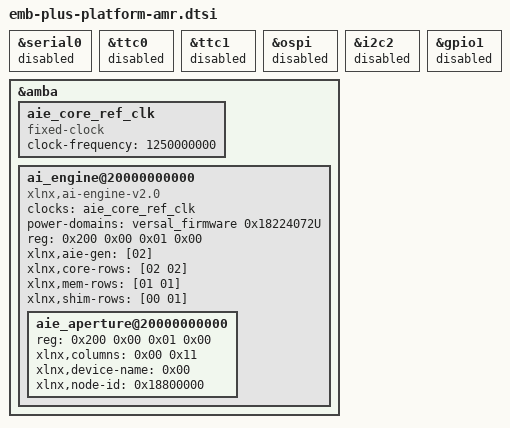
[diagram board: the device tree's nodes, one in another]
/*
 * SPDX-License-Identifier: GPL-2.0-only
 *
 * dtsi for Embedded Plus platform
 *
 * Copyright (C) 2024, Advanced Micro Devices, Inc.  All rights reserved.
 *
 */

&serial0 {
        status = "disabled";
};

&ttc0 {
        status = "disabled";
};
&ttc1 {
        status = "disabled";
};

&ospi {
        status = "disabled";
};

&i2c2 {
        status = "disabled";
};

&gpio1 {
        status = "disabled";
};

&amba {
        aie_core_ref_clk: aie_core_ref_clk {
                #clock-cells = <0x00>;
                clock-frequency = <1250000000>;
                compatible = "fixed-clock";
        };

        ai_engine@20000000000 {
                #address-cells = <0x02>;
                #size-cells = <0x02>;
                compatible = "xlnx,ai-engine-v2.0";
                clock-names = "aclk0";
                clocks = <&aie_core_ref_clk>;
		power-domains = <&versal_firmware 0x18224072U>;
                ranges;
                reg = <0x200 0x00 0x01 0x00>;
                xlnx,aie-gen = [02];
                xlnx,core-rows = [02 02];
                xlnx,mem-rows = [01 01];
                xlnx,shim-rows = [00 01];

                aie_aperture@20000000000 {
                        #address-cells = <0x02>;
                        #size-cells = <0x02>;
                        reg = <0x200 0x00 0x01 0x00>;
                        xlnx,columns = <0x00 0x11>;
                        xlnx,device-name = <0x00>;
                        xlnx,node-id = <0x18800000>;
                };
        };

};
